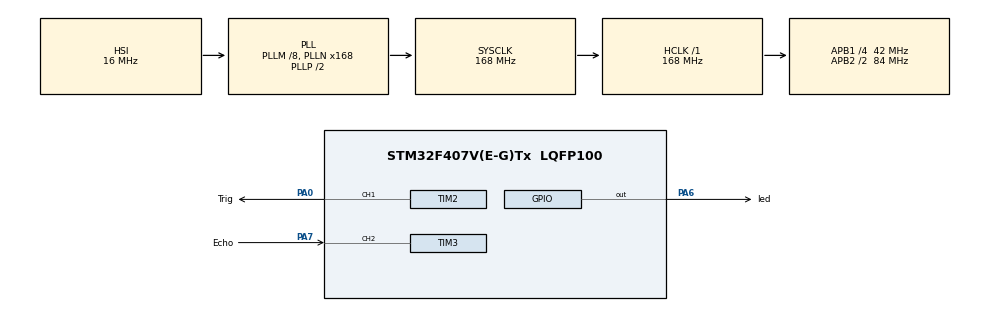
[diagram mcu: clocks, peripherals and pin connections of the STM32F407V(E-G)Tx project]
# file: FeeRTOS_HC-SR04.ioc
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FREERTOS.BinarySemaphores01=checkDisSem,Dynamic,NULL
FREERTOS.Tasks01=main,0,128,StartMain,Default,NULL,Dynamic,NULL,NULL;checkDistance,-1,128,StartCheckDistance,Default,NULL,Dynamic,NULL,NULL
Mcu.Family=STM32F4
Mcu.Name=STM32F407V(E-G)Tx
Mcu.Package=LQFP100
NVIC.PriorityGroup=NVIC_PRIORITYGROUP_4
NVIC.TIM2_IRQn=true\:10\:0\:true\:false\:true\:true\:true\:true
NVIC.TIM3_IRQn=true\:5\:0\:false\:false\:true\:true\:true\:true
NVIC.TIM6_DAC_IRQn=true\:0\:0\:false\:false\:true\:false\:false\:true
NVIC.TimeBase=TIM6_DAC_IRQn
NVIC.TimeBaseIP=TIM6
PA0-WKUP.GPIO_Label=Trig
PA0-WKUP.GPIO_PuPd=GPIO_PULLDOWN
PA0-WKUP.GPIO_Speed=GPIO_SPEED_FREQ_VERY_HIGH
PA0-WKUP.Signal=S_TIM2_CH1_ETR
PA13.Mode=Serial_Wire
PA13.Signal=SYS_JTMS-SWDIO
PA14.Mode=Serial_Wire
PA14.Signal=SYS_JTCK-SWCLK
PA6.GPIO_Label=led
PA6.GPIO_ModeDefaultOutputPP=GPIO_MODE_OUTPUT_PP
PA6.GPIO_PuPd=GPIO_PULLDOWN
PA6.Signal=GPIO_Output
PA7.GPIO_Label=Echo
PA7.GPIO_PuPd=GPIO_PULLDOWN
PA7.GPIO_Speed=GPIO_SPEED_FREQ_VERY_HIGH
PA7.Signal=S_TIM3_CH2
PH0-OSC_IN.Mode=HSE-External-Oscillator
PH0-OSC_IN.Signal=RCC_OSC_IN
PH1-OSC_OUT.Mode=HSE-External-Oscillator
PH1-OSC_OUT.Signal=RCC_OSC_OUT
ProjectManager.HeapSize=0x200
ProjectManager.StackSize=0x400
ProjectManager.TargetToolchain=STM32CubeIDE
RCC.48MHZClocksFreq_Value=84000000
RCC.AHBFreq_Value=168000000
RCC.APB1CLKDivider=RCC_HCLK_DIV4
RCC.APB1Freq_Value=42000000
RCC.APB1TimFreq_Value=84000000
RCC.APB2CLKDivider=RCC_HCLK_DIV2
RCC.APB2Freq_Value=84000000
RCC.APB2TimFreq_Value=168000000
RCC.CortexFreq_Value=168000000
RCC.HCLKFreq_Value=168000000
RCC.HSE_VALUE=8000000
RCC.HSICalibrationValue=16
RCC.HSI_VALUE=16000000
RCC.LSE_VALUE=32768
RCC.PLLM=8
RCC.PLLN=168
RCC.SYSCLKFreq_VALUE=168000000
RCC.SYSCLKSource=RCC_SYSCLKSOURCE_PLLCLK
RCC.VCOOutputFreq_Value=336000000
SH.S_TIM2_CH1_ETR.0=TIM2_CH1,Output Compare1 CH1
SH.S_TIM3_CH2.0=TIM3_CH2,Input_Capture2_from_TI2
TIM2.Channel-Output\ Compare1\ CH1=TIM_CHANNEL_1
TIM2.OCMode_1=TIM_OCMODE_TOGGLE
TIM2.Period=84 - 1
TIM2.Prescaler=1 - 1
TIM2.Pulse-Output\ Compare1\ CH1=10
TIM3.Channel-Input_Capture2_from_TI2=TIM_CHANNEL_2
TIM3.ICPolarity_CH2=TIM_INPUTCHANNELPOLARITY_BOTHEDGE
TIM3.Period=65535 - 1
TIM3.Prescaler=1281 - 1
VP_FREERTOS_VS_CMSIS_V1.Mode=CMSIS_V1
VP_SYS_VS_tim6.Mode=TIM6
VP_TIM2_VS_ClockSourceINT.Mode=Internal
VP_TIM3_VS_ClockSourceINT.Mode=Internal
board=custom

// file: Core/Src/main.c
/* USER CODE BEGIN Header */
/**
  ******************************************************************************
  * @file           : main.c
  * @brief          : Main program body
  ******************************************************************************
  * @attention
  *
  * <h2><center>&copy; Copyright (c) 2020 STMicroelectronics.
  * All rights reserved.</center></h2>
  *
  * This software component is licensed by ST under BSD 3-Clause license,
  * the "License"; You may not use this file except in compliance with the
  * License. You may obtain a copy of the License at:
  *                        opensource.org/licenses/BSD-3-Clause
  *
  ******************************************************************************
  */
/* USER CODE END Header */

#include "main.h"
#include "cmsis_os.h"

/* USER CODE BEGIN Includes */
#include "stdbool.h"
/* USER CODE END Includes */

TIM_HandleTypeDef htim2;
TIM_HandleTypeDef htim3;

osThreadId mainHandle;
osThreadId checkDistanceHandle;
osSemaphoreId checkDisSemHandle;
/* USER CODE BEGIN PV */
volatile uint32_t icValue1 = 0;
volatile uint32_t icValue2 = 0;
volatile uint32_t difference = 0;
volatile uint32_t frequency = 0;
volatile bool isFirstCaptured = true;
volatile uint32_t distance = 0;
/* USER CODE END PV */

void SystemClock_Config(void);
static void MX_GPIO_Init(void);
static void MX_TIM2_Init(void);
static void MX_TIM3_Init(void);
void StartMain(void const * argument);
void StartCheckDistance(void const * argument);

/* USER CODE BEGIN 0 */
void HAL_TIM_IC_CaptureCallback(TIM_HandleTypeDef *htim) {
	if (htim->Channel == HAL_TIM_ACTIVE_CHANNEL_2) {
		HAL_TIM_OC_Stop_IT(&htim2, TIM_CHANNEL_1);
		if (isFirstCaptured) {
			icValue1 = HAL_TIM_ReadCapturedValue(htim, TIM_CHANNEL_2);
			isFirstCaptured = false;
		}
		else if (!isFirstCaptured) {
			frequency = 84000000 / (htim3.Instance->PSC + 1);
			icValue2 = HAL_TIM_ReadCapturedValue(htim, TIM_CHANNEL_2);
			if (icValue2 >= icValue1) difference = icValue2 - icValue1;
			else difference = (htim3.Instance->ARR - icValue1) + icValue2;
//			distance = ((float)((difference / frequency) * 340) / 2) * 100;
			distance = (difference * 17000) / frequency;
			isFirstCaptured = true;
			HAL_TIM_IC_Stop_IT(&htim3, TIM_CHANNEL_2);
			if(distance > 30) osSemaphoreRelease(checkDisSemHandle);
		}
	}
}
void checkDistance() {
	icValue1 = 0;
	icValue2 = 0;
	distance = 0;
	isFirstCaptured = true;
	HAL_TIM_IC_Start_IT(&htim3, TIM_CHANNEL_2);
	HAL_TIM_OC_Start_IT(&htim2, TIM_CHANNEL_1);
}
/* USER CODE END 0 */

int main(void)
{

  /* MCU Configuration--------------------------------------------------------*/

  /* Reset of all peripherals, Initializes the Flash interface and the Systick. */
  HAL_Init();

  /* Configure the system clock */
  SystemClock_Config();

  /* Initialize all configured peripherals */
  MX_GPIO_Init();
  MX_TIM2_Init();
  MX_TIM3_Init();

  /* Create the semaphores(s) */
  /* definition and creation of checkDisSem */
  osSemaphoreDef(checkDisSem);
  checkDisSemHandle = osSemaphoreCreate(osSemaphore(checkDisSem), 1);

  /* Create the thread(s) */
  /* definition and creation of main */
  osThreadDef(main, StartMain, osPriorityNormal, 0, 128);
  mainHandle = osThreadCreate(osThread(main), NULL);

  /* definition and creation of checkDistance */
  osThreadDef(checkDistance, StartCheckDistance, osPriorityBelowNormal, 0, 128);
  checkDistanceHandle = osThreadCreate(osThread(checkDistance), NULL);

  /* Start scheduler */
  osKernelStart();

  /* We should never get here as control is now taken by the scheduler */
  /* Infinite loop */
  while (1)
  {

  }
}

void SystemClock_Config(void)
{
  RCC_OscInitTypeDef RCC_OscInitStruct = {0};
  RCC_ClkInitTypeDef RCC_ClkInitStruct = {0};

  /** Configure the main internal regulator output voltage
  */
  __HAL_RCC_PWR_CLK_ENABLE();
  __HAL_PWR_VOLTAGESCALING_CONFIG(PWR_REGULATOR_VOLTAGE_SCALE1);
  /** Initializes the CPU, AHB and APB busses clocks
  */
  RCC_OscInitStruct.OscillatorType = RCC_OSCILLATORTYPE_HSI;
  RCC_OscInitStruct.HSIState = RCC_HSI_ON;
  RCC_OscInitStruct.HSICalibrationValue = RCC_HSICALIBRATION_DEFAULT;
  RCC_OscInitStruct.PLL.PLLState = RCC_PLL_ON;
  RCC_OscInitStruct.PLL.PLLSource = RCC_PLLSOURCE_HSI;
  RCC_OscInitStruct.PLL.PLLM = 8;
  RCC_OscInitStruct.PLL.PLLN = 168;
  RCC_OscInitStruct.PLL.PLLP = RCC_PLLP_DIV2;
  RCC_OscInitStruct.PLL.PLLQ = 4;
  if (HAL_RCC_OscConfig(&RCC_OscInitStruct) != HAL_OK)
  {
    Error_Handler();
  }
  /** Initializes the CPU, AHB and APB busses clocks
  */
  RCC_ClkInitStruct.ClockType = RCC_CLOCKTYPE_HCLK|RCC_CLOCKTYPE_SYSCLK
                              |RCC_CLOCKTYPE_PCLK1|RCC_CLOCKTYPE_PCLK2;
  RCC_ClkInitStruct.SYSCLKSource = RCC_SYSCLKSOURCE_PLLCLK;
  RCC_ClkInitStruct.AHBCLKDivider = RCC_SYSCLK_DIV1;
  RCC_ClkInitStruct.APB1CLKDivider = RCC_HCLK_DIV4;
  RCC_ClkInitStruct.APB2CLKDivider = RCC_HCLK_DIV2;

  if (HAL_RCC_ClockConfig(&RCC_ClkInitStruct, FLASH_LATENCY_5) != HAL_OK)
  {
    Error_Handler();
  }
}

static void MX_TIM2_Init(void)
{

  TIM_ClockConfigTypeDef sClockSourceConfig = {0};
  TIM_MasterConfigTypeDef sMasterConfig = {0};
  TIM_OC_InitTypeDef sConfigOC = {0};

  htim2.Instance = TIM2;
  htim2.Init.Prescaler = 1 - 1;
  htim2.Init.CounterMode = TIM_COUNTERMODE_UP;
  htim2.Init.Period = 84 - 1;
  htim2.Init.ClockDivision = TIM_CLOCKDIVISION_DIV1;
  htim2.Init.AutoReloadPreload = TIM_AUTORELOAD_PRELOAD_DISABLE;
  if (HAL_TIM_Base_Init(&htim2) != HAL_OK)
  {
    Error_Handler();
  }
  sClockSourceConfig.ClockSource = TIM_CLOCKSOURCE_INTERNAL;
  if (HAL_TIM_ConfigClockSource(&htim2, &sClockSourceConfig) != HAL_OK)
  {
    Error_Handler();
  }
  if (HAL_TIM_OC_Init(&htim2) != HAL_OK)
  {
    Error_Handler();
  }
  sMasterConfig.MasterOutputTrigger = TIM_TRGO_RESET;
  sMasterConfig.MasterSlaveMode = TIM_MASTERSLAVEMODE_DISABLE;
  if (HAL_TIMEx_MasterConfigSynchronization(&htim2, &sMasterConfig) != HAL_OK)
  {
    Error_Handler();
  }
  sConfigOC.OCMode = TIM_OCMODE_TOGGLE;
  sConfigOC.Pulse = 10;
  sConfigOC.OCPolarity = TIM_OCPOLARITY_HIGH;
  sConfigOC.OCFastMode = TIM_OCFAST_DISABLE;
  if (HAL_TIM_OC_ConfigChannel(&htim2, &sConfigOC, TIM_CHANNEL_1) != HAL_OK)
  {
    Error_Handler();
  }
  HAL_TIM_MspPostInit(&htim2);

}

static void MX_TIM3_Init(void)
{

  TIM_ClockConfigTypeDef sClockSourceConfig = {0};
  TIM_MasterConfigTypeDef sMasterConfig = {0};
  TIM_IC_InitTypeDef sConfigIC = {0};

  htim3.Instance = TIM3;
  htim3.Init.Prescaler = 1281 - 1;
  htim3.Init.CounterMode = TIM_COUNTERMODE_UP;
  htim3.Init.Period = 65535 - 1;
  htim3.Init.ClockDivision = TIM_CLOCKDIVISION_DIV1;
  htim3.Init.AutoReloadPreload = TIM_AUTORELOAD_PRELOAD_DISABLE;
  if (HAL_TIM_Base_Init(&htim3) != HAL_OK)
  {
    Error_Handler();
  }
  sClockSourceConfig.ClockSource = TIM_CLOCKSOURCE_INTERNAL;
  if (HAL_TIM_ConfigClockSource(&htim3, &sClockSourceConfig) != HAL_OK)
  {
    Error_Handler();
  }
  if (HAL_TIM_IC_Init(&htim3) != HAL_OK)
  {
    Error_Handler();
  }
  sMasterConfig.MasterOutputTrigger = TIM_TRGO_RESET;
  sMasterConfig.MasterSlaveMode = TIM_MASTERSLAVEMODE_DISABLE;
  if (HAL_TIMEx_MasterConfigSynchronization(&htim3, &sMasterConfig) != HAL_OK)
  {
    Error_Handler();
  }
  sConfigIC.ICPolarity = TIM_INPUTCHANNELPOLARITY_BOTHEDGE;
  sConfigIC.ICSelection = TIM_ICSELECTION_DIRECTTI;
  sConfigIC.ICPrescaler = TIM_ICPSC_DIV1;
  sConfigIC.ICFilter = 0;
  if (HAL_TIM_IC_ConfigChannel(&htim3, &sConfigIC, TIM_CHANNEL_2) != HAL_OK)
  {
    Error_Handler();
  }

}

static void MX_GPIO_Init(void)
{
  GPIO_InitTypeDef GPIO_InitStruct = {0};

  /* GPIO Ports Clock Enable */
  __HAL_RCC_GPIOH_CLK_ENABLE();
  __HAL_RCC_GPIOA_CLK_ENABLE();

  /*Configure GPIO pin Output Level */
  HAL_GPIO_WritePin(led_GPIO_Port, led_Pin, GPIO_PIN_RESET);

  /*Configure GPIO pin : led_Pin */
  GPIO_InitStruct.Pin = led_Pin;
  GPIO_InitStruct.Mode = GPIO_MODE_OUTPUT_PP;
  GPIO_InitStruct.Pull = GPIO_PULLDOWN;
  GPIO_InitStruct.Speed = GPIO_SPEED_FREQ_LOW;
  HAL_GPIO_Init(led_GPIO_Port, &GPIO_InitStruct);

}

void StartMain(void const * argument)
{
  /* USER CODE BEGIN 5 */
  /* Infinite loop */
  for(;;)
  {
	  osSemaphoreWait(checkDisSemHandle, osWaitForever);
	  HAL_GPIO_TogglePin(led_GPIO_Port, led_Pin);
	  osDelay(100);
	  if(distance > 30) osSemaphoreRelease(checkDisSemHandle);
  }
  /* USER CODE END 5 */
}

void StartCheckDistance(void const * argument)
{
  /* USER CODE BEGIN StartCheckDistance */
  /* Infinite loop */
  for(;;)
  {
	  if(isFirstCaptured) checkDistance();
	  osDelay(100);
  }
  /* USER CODE END StartCheckDistance */
}

 /**
  * @brief  Period elapsed callback in non blocking mode
  * @note   This function is called  when TIM6 interrupt took place, inside
  * HAL_TIM_IRQHandler(). It makes a direct call to HAL_IncTick() to increment
  * a global variable "uwTick" used as application time base.
  * @param  htim : TIM handle
  * @retval None
  */
void HAL_TIM_PeriodElapsedCallback(TIM_HandleTypeDef *htim)
{
  if (htim->Instance == TIM6) {
    HAL_IncTick();
  }
}

void Error_Handler(void)
{
}

/************************ (C) COPYRIGHT STMicroelectronics *****END OF FILE****/
